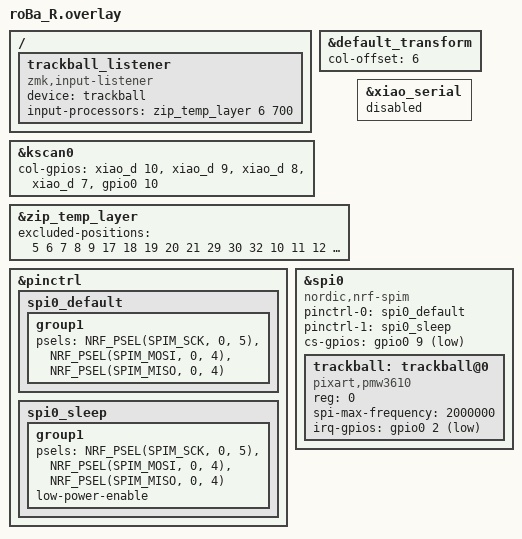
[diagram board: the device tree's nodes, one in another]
#include "roBa.dtsi"
#include <input/processors.dtsi>

&default_transform {
    col-offset = <6>;
};

&kscan0 {
        col-gpios
            = <&xiao_d 10 GPIO_ACTIVE_HIGH>
            , <&xiao_d 9 GPIO_ACTIVE_HIGH>
            , <&xiao_d 8 GPIO_ACTIVE_HIGH>
            , <&xiao_d 7 GPIO_ACTIVE_HIGH>
            , <&gpio0 10 GPIO_ACTIVE_HIGH>
            ;
};

/ {
    trackball_listener {
        status = "okay";
        compatible = "zmk,input-listener";
        device = <&trackball>;
        // ボールを動かすと MOUSE レイヤー(5)を ON、最後の動きから 700ms で OFF
        input-processors = <&zip_temp_layer 6 700>;
    };
};

// 自動マウスレイヤー（ZMK 標準の temp-layer）。
// ここに列挙した位置以外のキーを押すと MOUSE レイヤーを即解除し、そのキーは BASE のキーとして入力される。
// 位置番号は config/roBa.keymap の MOUSE レイヤーと対応させること。
&zip_temp_layer {
    excluded-positions = <
        5 6 7 8 9           // 右上段: 新規タブ復元 / 戻る / スクロール / 進む / 更新
        17 18 19 20 21      // 右中段: 新規タブ / 左・中・右クリック / 精密モード（押している間）
        29 30 32            // 右下段: タブを閉じる / 前のタブ / 次のタブ
        10 11 12 13         // 左ホームロウモッド (Win / Alt / Ctrl / Shift) → 修飾キー＋クリック用
    >;
};

&pinctrl {
    spi0_default: spi0_default {
        group1 {
            psels = <NRF_PSEL(SPIM_SCK, 0, 5)>,
                <NRF_PSEL(SPIM_MOSI, 0, 4)>,
                <NRF_PSEL(SPIM_MISO, 0, 4)>;
        };
    };

    spi0_sleep: spi0_sleep {
        group1 {
            psels = <NRF_PSEL(SPIM_SCK, 0, 5)>,
                <NRF_PSEL(SPIM_MOSI, 0, 4)>,
                <NRF_PSEL(SPIM_MISO, 0, 4)>;
            low-power-enable;
        };
    };
};

&xiao_serial { status = "disabled"; };

&spi0 {
    status = "okay";
    compatible = "nordic,nrf-spim";
    pinctrl-0 = <&spi0_default>;
    pinctrl-1 = <&spi0_sleep>;
    pinctrl-names = "default", "sleep";
    cs-gpios = <&gpio0 9 GPIO_ACTIVE_LOW>;

    trackball: trackball@0 {
        status = "okay";
        compatible = "pixart,pmw3610";
        reg = <0>;
        spi-max-frequency = <2000000>;
        irq-gpios = <&gpio0 2 (GPIO_ACTIVE_LOW | GPIO_PULL_UP)>;
    };
};
